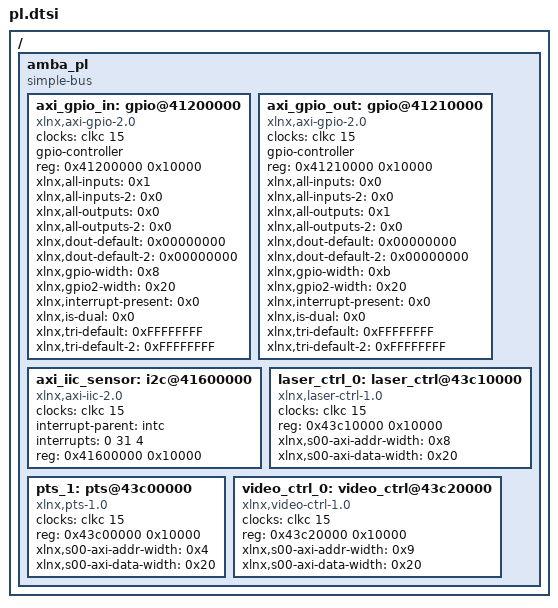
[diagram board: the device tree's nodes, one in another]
/*
 * CAUTION: This file is automatically generated by Xilinx.
 * Version:  
 * Today is: Mon Jan 18 13:38:43 2021
 */


/ {
	amba_pl: amba_pl {
		#address-cells = <1>;
		#size-cells = <1>;
		compatible = "simple-bus";
		ranges ;
		axi_gpio_in: gpio@41200000 {
			#gpio-cells = <3>;
			clock-names = "s_axi_aclk";
			clocks = <&clkc 15>;
			compatible = "xlnx,axi-gpio-2.0", "xlnx,xps-gpio-1.00.a";
			gpio-controller ;
			reg = <0x41200000 0x10000>;
			xlnx,all-inputs = <0x1>;
			xlnx,all-inputs-2 = <0x0>;
			xlnx,all-outputs = <0x0>;
			xlnx,all-outputs-2 = <0x0>;
			xlnx,dout-default = <0x00000000>;
			xlnx,dout-default-2 = <0x00000000>;
			xlnx,gpio-width = <0x8>;
			xlnx,gpio2-width = <0x20>;
			xlnx,interrupt-present = <0x0>;
			xlnx,is-dual = <0x0>;
			xlnx,tri-default = <0xFFFFFFFF>;
			xlnx,tri-default-2 = <0xFFFFFFFF>;
		};
		axi_gpio_out: gpio@41210000 {
			#gpio-cells = <3>;
			clock-names = "s_axi_aclk";
			clocks = <&clkc 15>;
			compatible = "xlnx,axi-gpio-2.0", "xlnx,xps-gpio-1.00.a";
			gpio-controller ;
			reg = <0x41210000 0x10000>;
			xlnx,all-inputs = <0x0>;
			xlnx,all-inputs-2 = <0x0>;
			xlnx,all-outputs = <0x1>;
			xlnx,all-outputs-2 = <0x0>;
			xlnx,dout-default = <0x00000000>;
			xlnx,dout-default-2 = <0x00000000>;
			xlnx,gpio-width = <0xb>;
			xlnx,gpio2-width = <0x20>;
			xlnx,interrupt-present = <0x0>;
			xlnx,is-dual = <0x0>;
			xlnx,tri-default = <0xFFFFFFFF>;
			xlnx,tri-default-2 = <0xFFFFFFFF>;
		};
		axi_iic_sensor: i2c@41600000 {
			#address-cells = <1>;
			#size-cells = <0>;
			clock-names = "s_axi_aclk";
			clocks = <&clkc 15>;
			compatible = "xlnx,axi-iic-2.0", "xlnx,xps-iic-2.00.a";
			interrupt-names = "iic2intc_irpt";
			interrupt-parent = <&intc>;
			interrupts = <0 31 4>;
			reg = <0x41600000 0x10000>;
		};
		laser_ctrl_0: laser_ctrl@43c10000 {
			clock-names = "s00_axi_aclk";
			clocks = <&clkc 15>;
			compatible = "xlnx,laser-ctrl-1.0";
			reg = <0x43c10000 0x10000>;
			xlnx,s00-axi-addr-width = <0x8>;
			xlnx,s00-axi-data-width = <0x20>;
		};
		pts_1: pts@43c00000 {
			clock-names = "s00_axi_aclk";
			clocks = <&clkc 15>;
			compatible = "xlnx,pts-1.0";
			reg = <0x43c00000 0x10000>;
			xlnx,s00-axi-addr-width = <0x4>;
			xlnx,s00-axi-data-width = <0x20>;
		};
		video_ctrl_0: video_ctrl@43c20000 {
			clock-names = "s00_axi_aclk";
			clocks = <&clkc 15>;
			compatible = "xlnx,video-ctrl-1.0";
			reg = <0x43c20000 0x10000>;
			xlnx,s00-axi-addr-width = <0x9>;
			xlnx,s00-axi-data-width = <0x20>;
		};
	};
};
